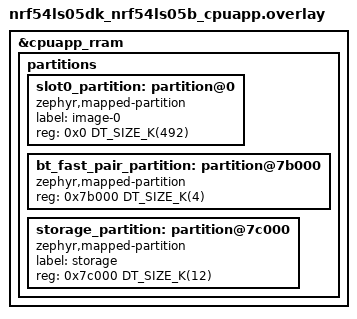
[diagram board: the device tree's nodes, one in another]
/*
 * Copyright (c) 2026 Nordic Semiconductor ASA
 *
 * SPDX-License-Identifier: LicenseRef-Nordic-5-Clause
 */

&cpuapp_rram {
	/* Redefine the "partitions" DTS node. */
	/delete-node/ partitions;

	partitions {
		ranges;
		#address-cells = <1>;
		#size-cells = <1>;

		slot0_partition: partition@0 {
			compatible = "zephyr,mapped-partition";
			label = "image-0";
			reg = <0x0 DT_SIZE_K(492)>;
		};

		bt_fast_pair_partition: partition@7b000 {
			compatible = "zephyr,mapped-partition";
			reg = <0x7b000 DT_SIZE_K(4)>;
		};

		storage_partition: partition@7c000 {
			compatible = "zephyr,mapped-partition";
			label = "storage";
			reg = <0x7c000 DT_SIZE_K(12)>;
		};
	};
};
